# des register map
Vendor: Texas Instruments
Peripheral module from a debugger description file (folder sc4ce290ncpz).
Registers are 32-bit, read-write, no defined reset value unless marked. A register's access mark holds for its fields unless they carry their own. Offsets are as the file gives them; lines under a group give offsets from that group; [hi:lo] are bit positions; {n}, {i} and the like mark numbered series; 'fields as' and 'values as' point back to an identical list; <NAME> marks a mode.

## DES — DES register offsets
0x00 DES_KEY3_L — DES Key 3 LSW for 192-Bit Key
  [31:0] DES_KEY3_L_KEY — Key Data
0x04 DES_KEY3_H — DES Key 3 MSW for 192-Bit Key
  [31:0] DES_KEY3_H_KEY — Key Data
0x08 DES_KEY2_L — DES Key 2 LSW for 128-Bit Key
  [31:0] DES_KEY2_L_KEY — Key Data
0x0C DES_KEY2_H — DES Key 2 MSW for 128-Bit Key
  [31:0] DES_KEY2_H_KEY — Key Data
0x10 DES_KEY1_L — DES Key 1 LSW for 64-Bit Key
  [31:0] DES_KEY1_L_KEY — Key Data
0x14 DES_KEY1_H — DES Key 1 MSW for 64-Bit Key
  [31:0] DES_KEY1_H_KEY — Key Data
0x18 DES_IV_L — DES Initialization Vector
  [31:0] DES_IV_L — Initialization vector for CBC, CFB modes (LSW)
0x1C DES_IV_H — DES Initialization Vector
  [31:0] DES_IV_H — Initialization vector for CBC, CFB modes (MSW)
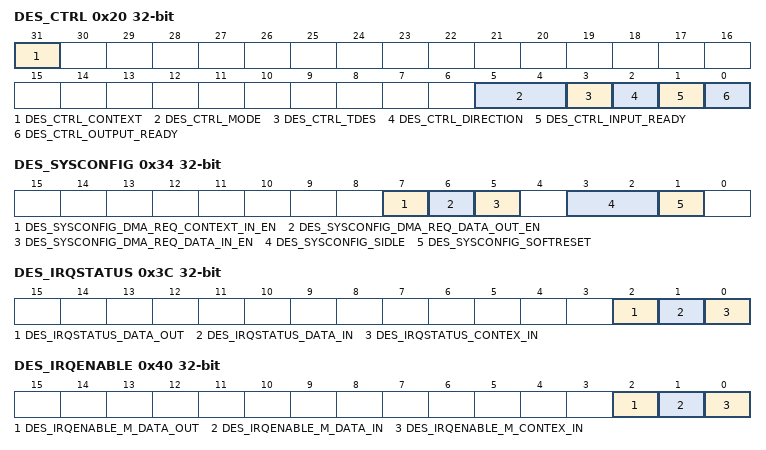
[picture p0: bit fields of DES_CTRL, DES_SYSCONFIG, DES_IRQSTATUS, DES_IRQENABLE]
0x20 DES_CTRL — DES Control
  [31] DES_CTRL_CONTEXT — If 1, this read-only status bit indicates that the context data registers can be overwritten and the host is permitted to write the next context
  [5:4] DES_CTRL_MODE — Select CBC, ECB or CFB mode0x0: ECB mode0x1: CBC mode0x2: CFB mode0x3: reserved
  [3] DES_CTRL_TDES — Select DES or triple DES encryption/decryption
  [2] DES_CTRL_DIRECTION — Select encryption/decryption 0x0: decryption is selected0x1: Encryption is selected
  [1] DES_CTRL_INPUT_READY — When 1, ready to encrypt/decrypt data
  [0] DES_CTRL_OUTPUT_READY — When 1, Data decrypted/encrypted ready
0x24 DES_LENGTH — DES Cryptographic Data Length
  [31:0] DES_LENGTH — Cryptographic data length in bytes for all modes
0x28 DES_DATA_L — DES LSW Data RW
  [31:0] DES_DATA_L — Data for encryption/decryption, LSW
0x2C DES_DATA_H — DES MSW Data RW
  [31:0] DES_DATA_H — Data for encryption/decryption, MSW
0x30 DES_REVISION ro — DES Revision Number
  [31:0] DES_REVISION — Revision number
0x34 DES_SYSCONFIG — DES System Configuration
  [7] DES_SYSCONFIG_DMA_REQ_CONTEXT_IN_EN — DMA Request Context In Enable
  [6] DES_SYSCONFIG_DMA_REQ_DATA_OUT_EN — DMA Request Data Out Enable
  [5] DES_SYSCONFIG_DMA_REQ_DATA_IN_EN — DMA Request Data In Enable
  [3:2] DES_SYSCONFIG_SIDLE — Sidle mode
    0=DES_SYSCONFIG_SIDLE_FORCE (Force-idle mode)
  [1] DES_SYSCONFIG_SOFTRESET — Soft reset
0x38 DES_SYSSTATUS ro — DES System Status
  [0] DES_SYSSTATUS_RESETDONE — Reset Done
0x3C DES_IRQSTATUS ro — DES Interrupt Status
  [2] DES_IRQSTATUS_DATA_OUT — This bit indicates data output interrupt is active and triggers the interrupt output
  [1] DES_IRQSTATUS_DATA_IN — This bit indicates data input interrupt is active and triggers the interrupt output
  [0] DES_IRQSTATUS_CONTEX_IN — This bit indicates context interrupt is active and triggers the interrupt output
0x40 DES_IRQENABLE — DES Interrupt Enable
  [2] DES_IRQENABLE_M_DATA_OUT — If this bit is set to 1 the data output interrupt is enabled
  [1] DES_IRQENABLE_M_DATA_IN — If this bit is set to 1 the data input interrupt is enabled
  [0] DES_IRQENABLE_M_CONTEX_IN — If this bit is set to 1 the context interrupt is enabled
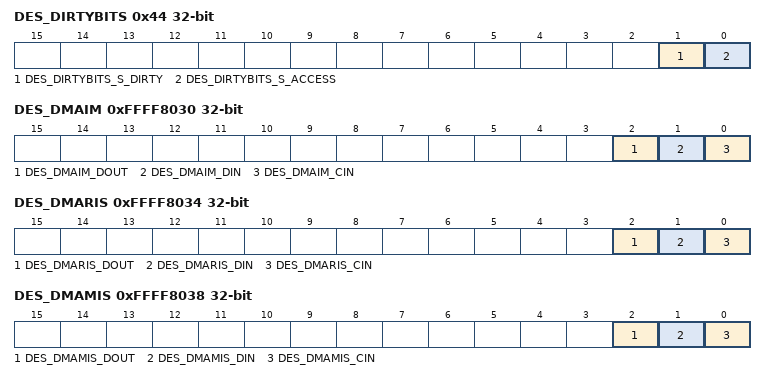
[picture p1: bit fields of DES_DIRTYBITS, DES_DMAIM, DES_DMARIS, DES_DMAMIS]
0x44 DES_DIRTYBITS
  [1] DES_DIRTYBITS_S_DIRTY — This bit is set to 1 by the module if any of the DES_* registers is written
  [0] DES_DIRTYBITS_S_ACCESS — This bit is set to 1 by the module if any of the DES_* registers is read
0xFFFF8030 DES_DMAIM — DES DMA Interrupt Mask
  [2] DES_DMAIM_DOUT — Data Out DMA Done Interrupt Mask
  [1] DES_DMAIM_DIN — Data In DMA Done Interrupt Mask
  [0] DES_DMAIM_CIN — Context In DMA Done Interrupt Mask
0xFFFF8034 DES_DMARIS ro — DES DMA Raw Interrupt Status
  [2] DES_DMARIS_DOUT — Data Out DMA Done Raw Interrupt Status
  [1] DES_DMARIS_DIN — Data In DMA Done Raw Interrupt Status
  [0] DES_DMARIS_CIN — Context In DMA Done Raw Interrupt Status
0xFFFF8038 DES_DMAMIS ro — DES DMA Masked Interrupt Status
  [2] DES_DMAMIS_DOUT — Data Out DMA Done Masked Interrupt Status
  [1] DES_DMAMIS_DIN — Data In DMA Done Masked Interrupt Status
  [0] DES_DMAMIS_CIN — Context In DMA Done Raw Interrupt Status
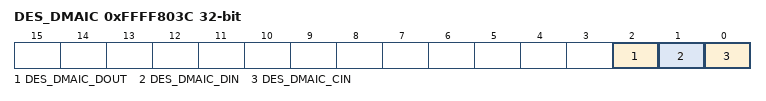
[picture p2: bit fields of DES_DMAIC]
0xFFFF803C DES_DMAIC wo — DES DMA Interrupt Clear
  [2] DES_DMAIC_DOUT — Data Out DMA Done Interrupt Clear
  [1] DES_DMAIC_DIN — Data In DMA Done Interrupt Clear
  [0] DES_DMAIC_CIN — Context In DMA Done Raw Interrupt Status
